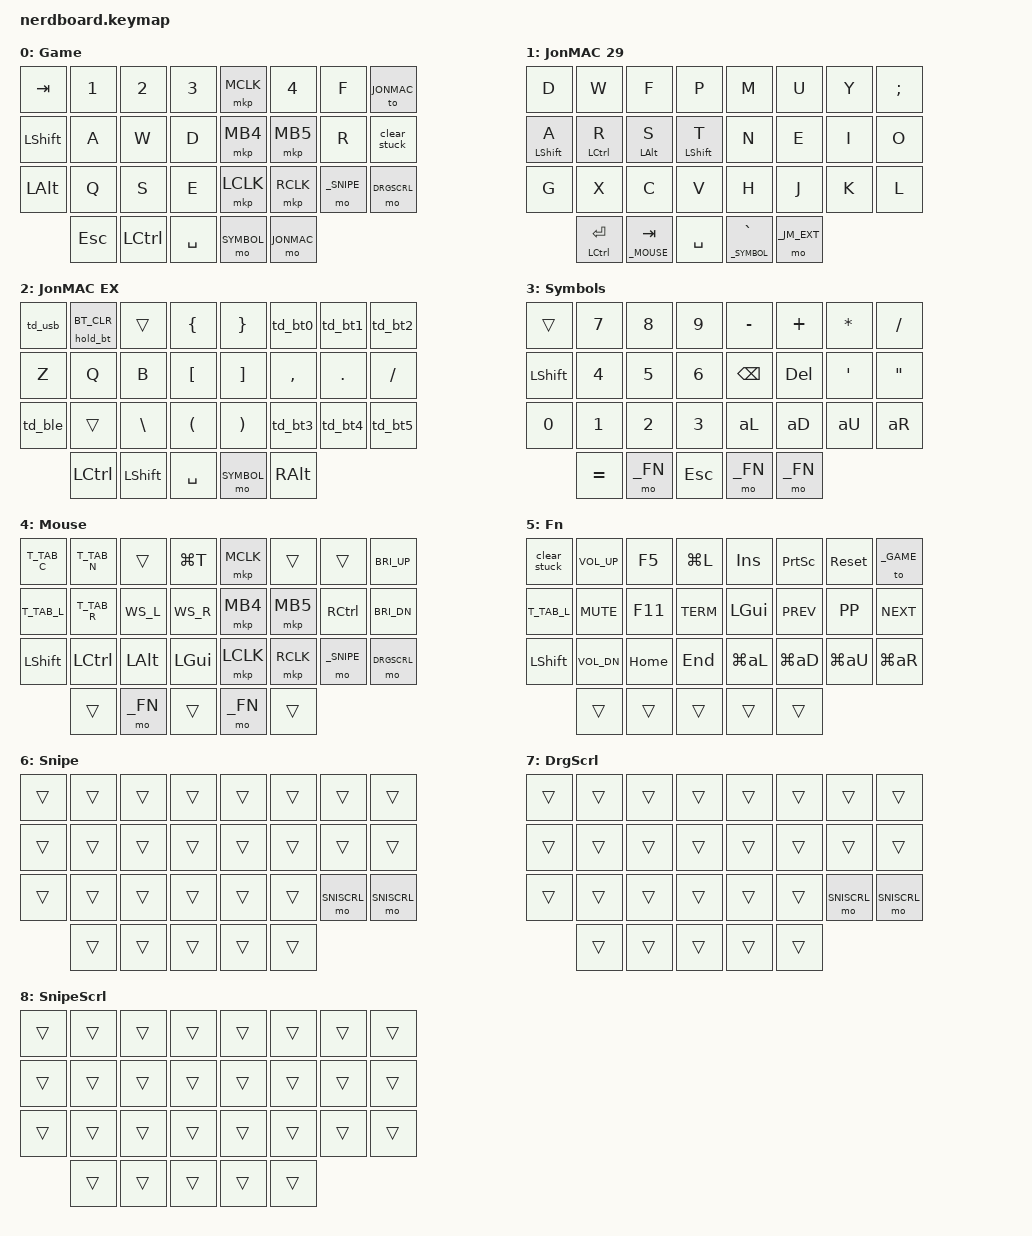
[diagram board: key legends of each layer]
/*
 * Copyright (c) 2020 The ZMK Contributors
 *
 * SPDX-License-Identifier: MIT
 */

#include <behaviors.dtsi>
#include <dt-bindings/zmk/keys.h>
#include <dt-bindings/zmk/bt.h>
#include <dt-bindings/zmk/mouse.h>
#include <dt-bindings/zmk/outputs.h>
#include <input/processors.dtsi>

// layer definitions
// If changing the _SNIPE or _DRGSCRL indexes also update them in boards/shields/nerdboard/nerdboard_right.overlay
#define _GAME    0
#define _JONMAC  1
#define _JM_EXT  2
#define _SYMBOL  3
#define _MOUSE   4
#define _FN      5
#define _SNIPE   6
#define _DRGSCRL 7
#define _SNISCRL 8

// layer modifiers
#define GAME    &to _GAME
#define JONMAC  &to _JONMAC
#define GJONMAC &mo _JONMAC
#define JM_EXT  &mo _JM_EXT
#define SYMBOL  &mo _SYMBOL
#define MOUSE   &mo _MOUSE
#define FN      &mo _FN
#define SNIPE   &mo _SNIPE
#define DRGSCRL &mo _DRGSCRL
#define SNISCRL &mo _SNISCRL

// layer tap
#define MO_TAB &lt _MOUSE  TAB
#define SY_GRV &lt _SYMBOL GRAVE

// alternate keys
#define aL      LEFT
#define aD      DOWN
#define aU      UP
#define aR      RIGHT
#define TERM    LC(LA(T))
#define WS_L    LG(PG_UP)
#define WS_R    LG(PG_DN)
#define T_TAB_L LC(PG_UP)
#define T_TAB_R LC(PG_DN)
#define T_TAB_N LS(LC(T))
#define T_TAB_C LS(LC(W))

// BT select / output keys fire on a double tap OR a 200ms hold; a single tap
// (e.g. rolling off JM_EXT onto L while typing "table") does nothing.
// The tap-dance waits its 200ms term, then presses the hold-tap; if the key is
// still held, the hold-tap's 1ms term makes it fire right away (~200ms total).
#define HOLD_OR_DT(name, hold, now) \
    name: name { \
        compatible = "zmk,behavior-tap-dance"; \
        #binding-cells = <0>; \
        tapping-term-ms = <200>; \
        bindings = <hold>, <now>; \
    };

/ {
    behaviors {
        HOLD_OR_DT(td_bt0, &hold_sel 0 0, &bt BT_SEL 0)
        HOLD_OR_DT(td_bt1, &hold_sel 1 0, &bt BT_SEL 1)
        HOLD_OR_DT(td_bt2, &hold_sel 2 0, &bt BT_SEL 2)
        HOLD_OR_DT(td_bt3, &hold_sel 3 0, &bt BT_SEL 3)
        HOLD_OR_DT(td_bt4, &hold_sel 4 0, &bt BT_SEL 4)
        HOLD_OR_DT(td_bt5, &hold_sel 5 0, &bt BT_SEL 5)
        HOLD_OR_DT(td_usb, &hold_out OUT_USB 0, &out OUT_USB)
        HOLD_OR_DT(td_ble, &hold_out OUT_BLE 0, &out OUT_BLE)

        hm: homerow_mods {
            compatible = "zmk,behavior-hold-tap";
            #binding-cells = <2>;
            flavor = "tap-preferred";
            tapping-term-ms = <200>;
            quick-tap-ms = <250>;
            require-prior-idle-ms = <125>;
            bindings = <&kp>, <&kp>;
        };

        // Only used inside HOLD_OR_DT: the tap-dance already supplies the 200ms delay.
        hold_sel: hold_sel {
            compatible = "zmk,behavior-hold-tap";
            #binding-cells = <2>;
            flavor = "tap-preferred";
            tapping-term-ms = <1>;
            bindings = <&bt_sel>, <&none>;
        };

        // BT clear waits 500ms
        hold_bt: hold_bt {
            compatible = "zmk,behavior-hold-tap";
            #binding-cells = <2>;
            flavor = "tap-preferred";
            tapping-term-ms = <500>;
            bindings = <&bt>, <&none>;
        };

        // Only used inside HOLD_OR_DT, same as hold_sel.
        hold_out: hold_out {
            compatible = "zmk,behavior-hold-tap";
            #binding-cells = <2>;
            flavor = "tap-preferred";
            tapping-term-ms = <1>;
            bindings = <&out>, <&none>;
        };
    };

    macros {
        // &bt needs two params; a hold-tap only passes one, so wrap BT_SEL.
        bt_sel: bt_sel {
            compatible = "zmk,behavior-macro-one-param";
            #binding-cells = <1>;
            bindings = <&macro_param_1to2>, <&bt BT_SEL MACRO_PLACEHOLDER>;
        };

        // Macro to clear stuck modifiers and mouse buttons
        clear_stuck: clear_stuck {
            compatible = "zmk,behavior-macro";
            #binding-cells = <0>;
            wait-ms = <10>;
            tap-ms = <10>;
            bindings
                = <&macro_release &kp LSHFT &kp RSHFT &kp LCTRL &kp RCTRL &kp LALT &kp RALT &kp LGUI &kp RGUI>
                , <&macro_release &mkp LCLK &mkp RCLK &mkp MCLK &mkp MB4 &mkp MB5>
                ;
        };
    };

    keymap {
        compatible = "zmk,keymap";

        game_layer {
            display-name = "Game";
            bindings = <
    &kp TAB   &kp N1  &kp N2    &kp N3          &mkp MCLK &kp N4     &kp F  JONMAC
    &kp LSHFT &kp A   &kp W     &kp D           &mkp MB4  &mkp MB5   &kp R  &clear_stuck
    &kp LALT  &kp Q   &kp S     &kp E           &mkp LCLK &mkp RCLK  SNIPE  DRGSCRL
              &kp ESC &kp LCTRL &kp SPACE       SYMBOL    GJONMAC
            >;
        };

        jon_mac_layer {
            display-name = "JonMAC 29";
            bindings = <
    &kp D       &kp W         &kp F       &kp P           &kp M   &kp U  &kp Y  &kp SEMI
    &hm LSHFT A &hm LCTRL R   &hm LALT S  &hm LSHIFT T    &kp N   &kp E  &kp I  &kp O
    &kp G       &kp X         &kp C       &kp V           &kp H   &kp J  &kp K  &kp L
                &hm LCTRL RET MO_TAB      &kp SPACE       SY_GRV  JM_EXT
            >;
        };

        jon_mac_ext_layer {
            display-name = "JonMAC EX";
            bindings = <
    &td_usb &hold_bt BT_CLR  &trans    &kp LBRC  &kp RBRC  &td_bt0   &td_bt1 &td_bt2
    &kp Z   &kp Q            &kp B     &kp LBKT  &kp RBKT  &kp COMMA &kp DOT &kp FSLH
    &td_ble &trans           &kp BSLH  &kp LPAR  &kp RPAR  &td_bt3   &td_bt4 &td_bt5
            &kp LCTRL        &kp LSHFT &kp SPACE SYMBOL    &kp RALT
            >;
        };

        symbol_layer {
            display-name = "Symbols";
            bindings = <
    &trans    &kp N7    &kp N8    &kp N9     &kp MINUS &kp PLUS  &kp ASTRK &kp FSLH
    &kp LSHFT &kp N4    &kp N5    &kp N6     &kp BSPC  &kp DEL   &kp SQT   &kp DQT
    &kp N0    &kp N1    &kp N2    &kp N3     &kp aL    &kp aD    &kp aU    &kp aR
              &kp EQUAL FN        &kp ESC    FN        FN
            >;
        };

        mouse_layer {
            display-name = "Mouse";
            bindings = <
    &kp T_TAB_C  &kp T_TAB_N  &trans    &kp LG(T)        &mkp MCLK &trans    &trans    &kp C_BRI_UP
    &kp T_TAB_L  &kp T_TAB_R  &kp WS_L  &kp WS_R         &mkp MB4  &mkp MB5  &kp RCTRL &kp C_BRI_DN
    &kp LSHFT    &kp LCTRL    &kp LALT  &kp LGUI         &mkp LCLK &mkp RCLK SNIPE     DRGSCRL
                 &trans       FN        &trans           FN        &trans
            >;
        };

        func_layer {
            display-name = "Fn";
            bindings = <
    &clear_stuck &kp K_VOL_UP  &kp F5    &kp LG(L)       &kp INS    &kp PSCRN  &sys_reset GAME
    &kp T_TAB_L  &kp K_MUTE    &kp F11   &kp TERM        &kp LGUI   &kp K_PREV &kp K_PP   &kp K_NEXT
    &kp LSHFT    &kp K_VOL_DN  &kp HOME  &kp END         &kp LG(aL) &kp LG(aD) &kp LG(aU) &kp LG(aR)
                 &trans        &trans    &trans          &trans     &trans
            >;
        };

        snipe_layer {
            display-name = "Snipe";
            bindings = <
    &trans &trans &trans &trans    &trans &trans &trans  &trans
    &trans &trans &trans &trans    &trans &trans &trans  &trans
    &trans &trans &trans &trans    &trans &trans SNISCRL SNISCRL
           &trans &trans &trans    &trans &trans
            >;
        };

        dragscroll_layer {
            display-name = "DrgScrl";
            bindings = <
    &trans &trans &trans &trans    &trans &trans &trans  &trans
    &trans &trans &trans &trans    &trans &trans &trans  &trans
    &trans &trans &trans &trans    &trans &trans SNISCRL SNISCRL
           &trans &trans &trans    &trans &trans
            >;
        };

        snipescroll_layer {
            display-name = "SnipeScrl";
            bindings = <
    &trans &trans &trans &trans    &trans &trans &trans &trans
    &trans &trans &trans &trans    &trans &trans &trans &trans
    &trans &trans &trans &trans    &trans &trans &trans &trans
           &trans &trans &trans    &trans &trans
            >;
        };
    };

};
